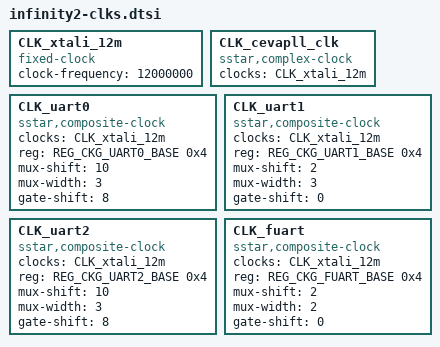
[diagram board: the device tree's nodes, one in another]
/*  */

CLK_xtali_12m: CLK_xtali_12m {
    #clock-cells = <0>;
    compatible = "fixed-clock";
    clock-frequency = <12000000>;
};

CLK_cevapll_clk: CLK_cevapll_clk {
    #clock-cells = <0>;
    compatible = "sstar,complex-clock";
    clocks = <&CLK_xtali_12m>;
};

CLK_uart0: CLK_uart0 {
    #clock-cells = <0>;
    compatible = "sstar,composite-clock";
    clocks = <&CLK_xtali_12m>;
    reg = <REG_CKG_UART0_BASE 0x4>;
    mux-shift = <10>;
    mux-width = <3>;
    gate-shift = <8>;
};

CLK_uart1: CLK_uart1 {
    #clock-cells = <0>;
    compatible = "sstar,composite-clock";
    clocks = <&CLK_xtali_12m>;
    reg = <REG_CKG_UART1_BASE 0x4>;
    mux-shift = <2>;  //2+REG_CKG_UART1_OFFSET 
    mux-width = <3>;//[4:2]: Select clock source
    gate-shift = <0>;  //0+REG_CKG_UART1_OFFSET
};

CLK_uart2: CLK_uart2 {
    #clock-cells = <0>;
    compatible = "sstar,composite-clock";
    clocks = <&CLK_xtali_12m>;
    reg = <REG_CKG_UART2_BASE 0x4>;
    mux-shift = <10>;  //10+REG_CKG_UART2_OFFSET 
    mux-width = <3>;//[4:2]: Select clock source
    gate-shift = <8>;  //8+REG_CKG_UART2_OFFSET
};

CLK_fuart: CLK_fuart {
    #clock-cells = <0>;
    compatible = "sstar,composite-clock";
    clocks = <&CLK_xtali_12m>;
    reg = <REG_CKG_FUART_BASE 0x4>;
    mux-shift = <2>;  //2+REG_CKG_UART2_OFFSET 
    mux-width = <2>;//[3:2]: Select clock source
    gate-shift = <0>;  //0+REG_CKG_UART2_OFFSET
};
